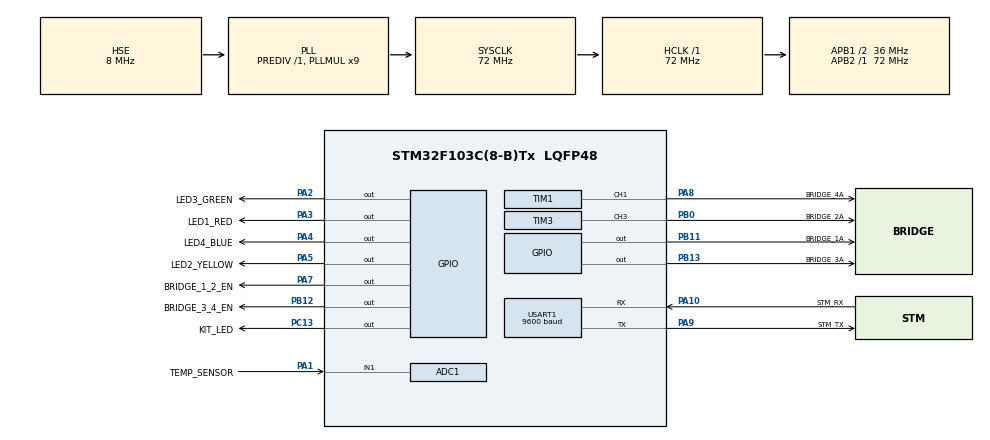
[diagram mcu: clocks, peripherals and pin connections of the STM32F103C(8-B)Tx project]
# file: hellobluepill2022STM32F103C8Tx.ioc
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ADC1.Channel-0\#ChannelRegularConversion=ADC_CHANNEL_1
ADC1.NbrOfConversionFlag=1
ADC1.Rank-0\#ChannelRegularConversion=1
ADC1.SamplingTime-0\#ChannelRegularConversion=ADC_SAMPLETIME_1CYCLE_5
ADC1.master=1
Dma.Request0=USART1_RX
Dma.Request1=USART1_TX
Dma.USART1_RX.0.Direction=DMA_PERIPH_TO_MEMORY
Dma.USART1_RX.0.Instance=DMA1_Channel5
Dma.USART1_RX.0.MemDataAlignment=DMA_MDATAALIGN_BYTE
Dma.USART1_RX.0.MemInc=DMA_MINC_ENABLE
Dma.USART1_RX.0.Mode=DMA_NORMAL
Dma.USART1_RX.0.PeriphDataAlignment=DMA_PDATAALIGN_BYTE
Dma.USART1_RX.0.PeriphInc=DMA_PINC_DISABLE
Dma.USART1_RX.0.Priority=DMA_PRIORITY_LOW
Dma.USART1_TX.1.Direction=DMA_MEMORY_TO_PERIPH
Dma.USART1_TX.1.Instance=DMA1_Channel4
Dma.USART1_TX.1.MemDataAlignment=DMA_MDATAALIGN_BYTE
Dma.USART1_TX.1.MemInc=DMA_MINC_ENABLE
Dma.USART1_TX.1.Mode=DMA_NORMAL
Dma.USART1_TX.1.PeriphDataAlignment=DMA_PDATAALIGN_BYTE
Dma.USART1_TX.1.PeriphInc=DMA_PINC_DISABLE
Dma.USART1_TX.1.Priority=DMA_PRIORITY_LOW
FREERTOS.BinarySemaphores01=ATCommandSemaphore,Static,ATCommandSemaphoreControlBlock;ATResponseSemaphore,Static,ATResponseSemaphoreControlBlock;UARTTXSemaphore,Static,UARTTXSemaphoreControlBlock;RadioStateSemaphore,Static,RadioStateSemaphoreControlBlock;LoRaTXSemaphore,Static,LoRaTXSemaphoreControlBlock
FREERTOS.Events01=ModemStatusFlags,Static,ModemStatusFlagsControlBlock
FREERTOS.Queues01=uartQueue,4,void*,0,Static,uartQueueBuffer,uartQueueControlBlock;ATQueue,4,void*,0,Static,ATQueueBuffer,ATQueueControlBlock;ModemSendQueue,4,void*,0,Static,ModemSendQueueBuffer,ModemSendQueueControlBlock;TemperatureQueue,8,uint32_t,0,Static,TemperatureQueueBuffer,TemperatureQueueControlBlock
FREERTOS.Tasks01=defaultTask,24,128,StartDefaultTask,Default,NULL,Dynamic,NULL,NULL;ATParsingTask,39,256,ATParsingTaskCode,As external,NULL,Static,ATParsingTaskBuffer,ATParsingTaskControlBlock;ATHandlingTask,38,256,ATHandlingTaskCode,As external,NULL,Static,ATHandlingTaskBuffer,ATHandlingTaskControlBlock;UARTProcTask,47,256,UARTProcTaskCode,As external,NULL,Static,UARTProcTaskBuffer,UARTProcTaskControlBlock;ModemMngrTask,31,256,ModemManagerTaskCode,As external,NULL,Static,ModemMngrTaskBuffer,ModemMngrTaskControlBlock;AppSendTask,15,256,AppSendTaskCode,As external,NULL,Static,SendTemperatureBuffer,SendTemperatureControlBlock;ReadFromADCTask,15,128,ReadFromADCTaskCode,As external,NULL,Static,ReadFromADCTaskBuffer,ReadFromADCTaskControlBlock
FREERTOS.Timers01=PeriodicSendTimer,PeriodicSendTimerCallback,osTimerPeriodic,As external,NULL,Static,PeriodicSendTimerControlBlock;ModemLedTimer,ModemLedCallback,osTimerPeriodic,As external,NULL,Static,ModemLedTimerControlBlock;DutyCycleTimer,DutyCycleTimerCallback,osTimerOnce,As external,NULL,Static,DutyCycleTimerControlBlock
FREERTOS.configTOTAL_HEAP_SIZE=2048
FREERTOS.configUSE_TICKLESS_IDLE=1
Mcu.Family=STM32F1
Mcu.Name=STM32F103C(8-B)Tx
Mcu.Package=LQFP48
NVIC.DMA1_Channel4_IRQn=true\:5\:0\:false\:false\:true\:true\:false\:true\:true
NVIC.DMA1_Channel5_IRQn=true\:5\:0\:false\:false\:true\:true\:false\:true\:true
NVIC.PriorityGroup=NVIC_PRIORITYGROUP_4
NVIC.TIM1_TRG_COM_IRQn=true\:5\:0\:false\:false\:true\:true\:true\:true\:true
NVIC.TIM4_IRQn=true\:15\:0\:false\:false\:true\:false\:false\:true\:true
NVIC.TimeBase=TIM4_IRQn
NVIC.TimeBaseIP=TIM4
NVIC.USART1_IRQn=true\:5\:0\:false\:false\:true\:true\:true\:true\:true
PA1.GPIO_Label=TEMP_SENSOR
PA1.Signal=ADCx_IN1
PA10.GPIO_Label=STM_RX
PA10.Mode=Asynchronous
PA10.Signal=USART1_RX
PA13.Mode=Serial_Wire
PA13.Signal=SYS_JTMS-SWDIO
PA14.Mode=Serial_Wire
PA14.Signal=SYS_JTCK-SWCLK
PA2.GPIO_Label=LED3_GREEN
PA2.Signal=GPIO_Output
PA3.GPIO_Label=LED1_RED
PA3.Signal=GPIO_Output
PA4.GPIO_Label=LED4_BLUE
PA4.Signal=GPIO_Output
PA5.GPIO_Label=LED2_YELLOW
PA5.Signal=GPIO_Output
PA7.GPIO_Label=BRIDGE_1_2_EN
PA7.PinState=GPIO_PIN_SET
PA7.Signal=GPIO_Output
PA8.GPIO_Label=BRIDGE_4A
PA8.Signal=S_TIM1_CH1
PA9.GPIO_Label=STM_TX
PA9.Mode=Asynchronous
PA9.Signal=USART1_TX
PB0.GPIO_Label=BRIDGE_2A
PB0.Signal=S_TIM3_CH3
PB11.GPIO_Label=BRIDGE_1A
PB11.PinState=GPIO_PIN_RESET
PB11.Signal=GPIO_Output
PB12.GPIO_Label=BRIDGE_3_4_EN
PB12.PinState=GPIO_PIN_SET
PB12.Signal=GPIO_Output
PB13.GPIO_Label=BRIDGE_3A
PB13.Signal=GPIO_Output
PC13-TAMPER-RTC.GPIO_Label=KIT_LED
PC13-TAMPER-RTC.Signal=GPIO_Output
PC14-OSC32_IN.Mode=LSE-External-Oscillator
PC14-OSC32_IN.Signal=RCC_OSC32_IN
PC15-OSC32_OUT.Mode=LSE-External-Oscillator
PC15-OSC32_OUT.Signal=RCC_OSC32_OUT
PD0-OSC_IN.Mode=HSE-External-Oscillator
PD0-OSC_IN.Signal=RCC_OSC_IN
PD1-OSC_OUT.Mode=HSE-External-Oscillator
PD1-OSC_OUT.Signal=RCC_OSC_OUT
ProjectManager.HeapSize=0x200
ProjectManager.StackSize=0x400
ProjectManager.TargetToolchain=Makefile
RCC.ADCPresc=RCC_ADCPCLK2_DIV6
RCC.AHBFreq_Value=72000000
RCC.APB1CLKDivider=RCC_HCLK_DIV2
RCC.APB1Freq_Value=36000000
RCC.APB1TimFreq_Value=72000000
RCC.APB2Freq_Value=72000000
RCC.APB2TimFreq_Value=72000000
RCC.HCLKFreq_Value=72000000
RCC.PLLMUL=RCC_PLL_MUL9
RCC.PLLSourceVirtual=RCC_PLLSOURCE_HSE
RCC.SYSCLKFreq_VALUE=72000000
RCC.SYSCLKSource=RCC_SYSCLKSOURCE_PLLCLK
RCC.USBFreq_Value=48000000
RCC.USBPrescaler=RCC_USBCLKSOURCE_PLL_DIV1_5
SH.ADCx_IN1.0=ADC1_IN1,IN1
SH.S_TIM1_CH1.0=TIM1_CH1,Output Compare1 CH1
SH.S_TIM3_CH3.0=TIM3_CH3,PWM Generation3 CH3
TIM1.Channel-Output\ Compare1\ CH1=TIM_CHANNEL_1
TIM1.OC1Preload=ENABLE
TIM1.OCMode_1=TIM_OCMODE_TOGGLE
TIM1.Period=7200-1
TIM1.Pulse-Output\ Compare1\ CH1=7200-1
TIM3.Channel-PWM\ Generation3\ CH3=TIM_CHANNEL_3
TIM3.Period=7200-1
TIM3.Prescaler=0
TIM3.Pulse-PWM\ Generation3\ CH3=7200-1
USART1.BaudRate=9600
USART1.VirtualMode=VM_ASYNC
VP_FREERTOS_VS_CMSIS_V2.Mode=CMSIS_V2
VP_SYS_VS_tim4.Mode=TIM4
VP_TIM1_VS_ClockSourceINT.Mode=Internal
VP_TIM3_VS_ClockSourceINT.Mode=Internal
board=custom

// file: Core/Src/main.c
/* USER CODE BEGIN Header */
/**
  ******************************************************************************
  * @file           : main.c
  * @brief          : Main program body
  ******************************************************************************
  * @attention
  *
  * Copyright (c) 2022 STMicroelectronics.
  * All rights reserved.
  *
  * This software is licensed under terms that can be found in the LICENSE file
  * in the root directory of this software component.
  * If no LICENSE file comes with this software, it is provided AS-IS.
  *
  ******************************************************************************
  */
/* USER CODE END Header */
#include "main.h"
#include "cmsis_os.h"

typedef StaticTask_t osStaticThreadDef_t;
typedef StaticQueue_t osStaticMessageQDef_t;
typedef StaticTimer_t osStaticTimerDef_t;
typedef StaticSemaphore_t osStaticSemaphoreDef_t;
typedef StaticEventGroup_t osStaticEventGroupDef_t;

ADC_HandleTypeDef hadc1;

TIM_HandleTypeDef htim1;
TIM_HandleTypeDef htim3;

UART_HandleTypeDef huart1;
DMA_HandleTypeDef hdma_usart1_rx;
DMA_HandleTypeDef hdma_usart1_tx;

/* Definitions for defaultTask */
osThreadId_t defaultTaskHandle;
const osThreadAttr_t defaultTask_attributes = {
  .name = "defaultTask",
  .stack_size = 128 * 4,
  .priority = (osPriority_t) osPriorityNormal,
};
/* Definitions for ATParsingTask */
osThreadId_t ATParsingTaskHandle;
uint32_t ATParsingTaskBuffer[ 256 ];
osStaticThreadDef_t ATParsingTaskControlBlock;
const osThreadAttr_t ATParsingTask_attributes = {
  .name = "ATParsingTask",
  .cb_mem = &ATParsingTaskControlBlock,
  .cb_size = sizeof(ATParsingTaskControlBlock),
  .stack_mem = &ATParsingTaskBuffer[0],
  .stack_size = sizeof(ATParsingTaskBuffer),
  .priority = (osPriority_t) osPriorityAboveNormal7,
};
/* Definitions for ATHandlingTask */
osThreadId_t ATHandlingTaskHandle;
uint32_t ATHandlingTaskBuffer[ 256 ];
osStaticThreadDef_t ATHandlingTaskControlBlock;
const osThreadAttr_t ATHandlingTask_attributes = {
  .name = "ATHandlingTask",
  .cb_mem = &ATHandlingTaskControlBlock,
  .cb_size = sizeof(ATHandlingTaskControlBlock),
  .stack_mem = &ATHandlingTaskBuffer[0],
  .stack_size = sizeof(ATHandlingTaskBuffer),
  .priority = (osPriority_t) osPriorityAboveNormal6,
};
/* Definitions for UARTProcTask */
osThreadId_t UARTProcTaskHandle;
uint32_t UARTProcTaskBuffer[ 256 ];
osStaticThreadDef_t UARTProcTaskControlBlock;
const osThreadAttr_t UARTProcTask_attributes = {
  .name = "UARTProcTask",
  .cb_mem = &UARTProcTaskControlBlock,
  .cb_size = sizeof(UARTProcTaskControlBlock),
  .stack_mem = &UARTProcTaskBuffer[0],
  .stack_size = sizeof(UARTProcTaskBuffer),
  .priority = (osPriority_t) osPriorityHigh7,
};
/* Definitions for ModemMngrTask */
osThreadId_t ModemMngrTaskHandle;
uint32_t ModemMngrTaskBuffer[ 256 ];
osStaticThreadDef_t ModemMngrTaskControlBlock;
const osThreadAttr_t ModemMngrTask_attributes = {
  .name = "ModemMngrTask",
  .cb_mem = &ModemMngrTaskControlBlock,
  .cb_size = sizeof(ModemMngrTaskControlBlock),
  .stack_mem = &ModemMngrTaskBuffer[0],
  .stack_size = sizeof(ModemMngrTaskBuffer),
  .priority = (osPriority_t) osPriorityNormal7,
};
/* Definitions for AppSendTask */
osThreadId_t AppSendTaskHandle;
uint32_t SendTemperatureBuffer[ 256 ];
osStaticThreadDef_t SendTemperatureControlBlock;
const osThreadAttr_t AppSendTask_attributes = {
  .name = "AppSendTask",
  .cb_mem = &SendTemperatureControlBlock,
  .cb_size = sizeof(SendTemperatureControlBlock),
  .stack_mem = &SendTemperatureBuffer[0],
  .stack_size = sizeof(SendTemperatureBuffer),
  .priority = (osPriority_t) osPriorityLow7,
};
/* Definitions for ReadFromADCTask */
osThreadId_t ReadFromADCTaskHandle;
uint32_t ReadFromADCTaskBuffer[ 128 ];
osStaticThreadDef_t ReadFromADCTaskControlBlock;
const osThreadAttr_t ReadFromADCTask_attributes = {
  .name = "ReadFromADCTask",
  .cb_mem = &ReadFromADCTaskControlBlock,
  .cb_size = sizeof(ReadFromADCTaskControlBlock),
  .stack_mem = &ReadFromADCTaskBuffer[0],
  .stack_size = sizeof(ReadFromADCTaskBuffer),
  .priority = (osPriority_t) osPriorityLow7,
};
/* Definitions for uartQueue */
osMessageQueueId_t uartQueueHandle;
uint8_t uartQueueBuffer[ 4 * sizeof( void* ) ];
osStaticMessageQDef_t uartQueueControlBlock;
const osMessageQueueAttr_t uartQueue_attributes = {
  .name = "uartQueue",
  .cb_mem = &uartQueueControlBlock,
  .cb_size = sizeof(uartQueueControlBlock),
  .mq_mem = &uartQueueBuffer,
  .mq_size = sizeof(uartQueueBuffer)
};
/* Definitions for ATQueue */
osMessageQueueId_t ATQueueHandle;
uint8_t ATQueueBuffer[ 4 * sizeof( void* ) ];
osStaticMessageQDef_t ATQueueControlBlock;
const osMessageQueueAttr_t ATQueue_attributes = {
  .name = "ATQueue",
  .cb_mem = &ATQueueControlBlock,
  .cb_size = sizeof(ATQueueControlBlock),
  .mq_mem = &ATQueueBuffer,
  .mq_size = sizeof(ATQueueBuffer)
};
/* Definitions for ModemSendQueue */
osMessageQueueId_t ModemSendQueueHandle;
uint8_t ModemSendQueueBuffer[ 4 * sizeof( void* ) ];
osStaticMessageQDef_t ModemSendQueueControlBlock;
const osMessageQueueAttr_t ModemSendQueue_attributes = {
  .name = "ModemSendQueue",
  .cb_mem = &ModemSendQueueControlBlock,
  .cb_size = sizeof(ModemSendQueueControlBlock),
  .mq_mem = &ModemSendQueueBuffer,
  .mq_size = sizeof(ModemSendQueueBuffer)
};
/* Definitions for PeriodicSendTimer */
osTimerId_t PeriodicSendTimerHandle;
osStaticTimerDef_t PeriodicSendTimerControlBlock;
const osTimerAttr_t PeriodicSendTimer_attributes = {
  .name = "PeriodicSendTimer",
  .cb_mem = &PeriodicSendTimerControlBlock,
  .cb_size = sizeof(PeriodicSendTimerControlBlock),
};
/* Definitions for TemperatureQueue */
osMessageQueueId_t TemperatureQueueHandle;
uint8_t TemperatureQueueBuffer[ 8 * sizeof( uint32_t ) ];
osStaticMessageQDef_t TemperatureQueueControlBlock;
const osMessageQueueAttr_t TemperatureQueue_attributes = {
  .name = "TemperatureQueue",
  .cb_mem = &TemperatureQueueControlBlock,
  .cb_size = sizeof(TemperatureQueueControlBlock),
  .mq_mem = &TemperatureQueueBuffer,
  .mq_size = sizeof(TemperatureQueueBuffer)
};
/* Definitions for ModemLedTimer */
osTimerId_t ModemLedTimerHandle;
osStaticTimerDef_t ModemLedTimerControlBlock;
const osTimerAttr_t ModemLedTimer_attributes = {
  .name = "ModemLedTimer",
  .cb_mem = &ModemLedTimerControlBlock,
  .cb_size = sizeof(ModemLedTimerControlBlock),
};
/* Definitions for DutyCycleTimer */
osTimerId_t DutyCycleTimerHandle;
osStaticTimerDef_t DutyCycleTimerControlBlock;
const osTimerAttr_t DutyCycleTimer_attributes = {
  .name = "DutyCycleTimer",
  .cb_mem = &DutyCycleTimerControlBlock,
  .cb_size = sizeof(DutyCycleTimerControlBlock),
};
/* Definitions for ATCommandSemaphore */
osSemaphoreId_t ATCommandSemaphoreHandle;
osStaticSemaphoreDef_t ATCommandSemaphoreControlBlock;
const osSemaphoreAttr_t ATCommandSemaphore_attributes = {
  .name = "ATCommandSemaphore",
  .cb_mem = &ATCommandSemaphoreControlBlock,
  .cb_size = sizeof(ATCommandSemaphoreControlBlock),
};
/* Definitions for ATResponseSemaphore */
osSemaphoreId_t ATResponseSemaphoreHandle;
osStaticSemaphoreDef_t ATResponseSemaphoreControlBlock;
const osSemaphoreAttr_t ATResponseSemaphore_attributes = {
  .name = "ATResponseSemaphore",
  .cb_mem = &ATResponseSemaphoreControlBlock,
  .cb_size = sizeof(ATResponseSemaphoreControlBlock),
};
/* Definitions for UARTTXSemaphore */
osSemaphoreId_t UARTTXSemaphoreHandle;
osStaticSemaphoreDef_t UARTTXSemaphoreControlBlock;
const osSemaphoreAttr_t UARTTXSemaphore_attributes = {
  .name = "UARTTXSemaphore",
  .cb_mem = &UARTTXSemaphoreControlBlock,
  .cb_size = sizeof(UARTTXSemaphoreControlBlock),
};
/* Definitions for RadioStateSemaphore */
osSemaphoreId_t RadioStateSemaphoreHandle;
osStaticSemaphoreDef_t RadioStateSemaphoreControlBlock;
const osSemaphoreAttr_t RadioStateSemaphore_attributes = {
  .name = "RadioStateSemaphore",
  .cb_mem = &RadioStateSemaphoreControlBlock,
  .cb_size = sizeof(RadioStateSemaphoreControlBlock),
};
/* Definitions for LoRaTXSemaphore */
osSemaphoreId_t LoRaTXSemaphoreHandle;
osStaticSemaphoreDef_t LoRaTXSemaphoreControlBlock;
const osSemaphoreAttr_t LoRaTXSemaphore_attributes = {
  .name = "LoRaTXSemaphore",
  .cb_mem = &LoRaTXSemaphoreControlBlock,
  .cb_size = sizeof(LoRaTXSemaphoreControlBlock),
};
/* Definitions for ModemStatusFlags */
osEventFlagsId_t ModemStatusFlagsHandle;
osStaticEventGroupDef_t ModemStatusFlagsControlBlock;
const osEventFlagsAttr_t ModemStatusFlags_attributes = {
  .name = "ModemStatusFlags",
  .cb_mem = &ModemStatusFlagsControlBlock,
  .cb_size = sizeof(ModemStatusFlagsControlBlock),
};

void SystemClock_Config(void);
static void MX_GPIO_Init(void);
static void MX_DMA_Init(void);
static void MX_USART1_UART_Init(void);
static void MX_ADC1_Init(void);
static void MX_TIM3_Init(void);
static void MX_TIM1_Init(void);
void StartDefaultTask(void *argument);
extern void ATParsingTaskCode(void *argument);
extern void ATHandlingTaskCode(void *argument);
extern void UARTProcTaskCode(void *argument);
extern void ModemManagerTaskCode(void *argument);
extern void AppSendTaskCode(void *argument);
extern void PeriodicSendTimerCallback(void *argument);
extern void ReadFromADCTaskCode(void *argument);
extern void ModemLedCallback(void *argument);
extern void DutyCycleTimerCallback(void *argument);

/* USER CODE BEGIN PFP */
void CONFIGURE_TIMER_FOR_RUN_TIME_STATS()
{
  HAL_TIM_Base_Start(&htim3); /* Define this to initialize your timer/counter */
}

uint32_t GET_RUN_TIME_COUNTER_VALUE()
{
  return __HAL_TIM_GET_COUNTER(&htim3); /* Define this to sample the timer/counter */
}

/* USER CODE END PFP */

/* USER CODE BEGIN 0 */
const volatile int uxTopUsedPriority = configMAX_PRIORITIES - 1; //this declaration enables thread awareness for FreeRTOS using OpenOCD

// Paste this code to Core/Inc/FreeRTOSConfig.h to enable kernel statistics (will be overwritten by STMCubeMX everytime code is generated)
// #define portCONFIGURE_TIMER_FOR_RUN_TIME_STATS() CONFIGURE_TIMER_FOR_RUN_TIME_STATS()/* Define this to initialize your timer/counter */
// #define portGET_RUN_TIME_COUNTER_VALUE() GET_RUN_TIME_COUNTER_VALUE()        /* Define this to sample the timer/counter */
// #define configGENERATE_RUN_TIME_STATS (1)
// #define configRECORD_STACK_HIGH_ADDRESS (1)
/* USER CODE END 0 */

int main(void)
{
  /* USER CODE BEGIN 1 */
  uint32_t i;
  (void)uxTopUsedPriority; //this declaration enables thread awareness for FreeRTOS using OpenOCD
  /* USER CODE END 1 */

  /* MCU Configuration--------------------------------------------------------*/

  /* Reset of all peripherals, Initializes the Flash interface and the Systick. */
  HAL_Init();

  /* Configure the system clock */
  SystemClock_Config();

  /* Initialize all configured peripherals */
  MX_GPIO_Init();
  MX_DMA_Init();
  MX_USART1_UART_Init();
  MX_ADC1_Init();
  MX_TIM3_Init();
  MX_TIM1_Init();

  /* Init scheduler */
  osKernelInitialize();

  /* Create the semaphores(s) */
  /* creation of ATCommandSemaphore */
  ATCommandSemaphoreHandle = osSemaphoreNew(1, 1, &ATCommandSemaphore_attributes);

  /* creation of ATResponseSemaphore */
  ATResponseSemaphoreHandle = osSemaphoreNew(1, 1, &ATResponseSemaphore_attributes);

  /* creation of UARTTXSemaphore */
  UARTTXSemaphoreHandle = osSemaphoreNew(1, 1, &UARTTXSemaphore_attributes);

  /* creation of RadioStateSemaphore */
  RadioStateSemaphoreHandle = osSemaphoreNew(1, 1, &RadioStateSemaphore_attributes);

  /* creation of LoRaTXSemaphore */
  LoRaTXSemaphoreHandle = osSemaphoreNew(1, 1, &LoRaTXSemaphore_attributes);

  /* Create the timer(s) */
  /* creation of PeriodicSendTimer */
  PeriodicSendTimerHandle = osTimerNew(PeriodicSendTimerCallback, osTimerPeriodic, NULL, &PeriodicSendTimer_attributes);

  /* creation of ModemLedTimer */
  ModemLedTimerHandle = osTimerNew(ModemLedCallback, osTimerPeriodic, NULL, &ModemLedTimer_attributes);

  /* creation of DutyCycleTimer */
  DutyCycleTimerHandle = osTimerNew(DutyCycleTimerCallback, osTimerOnce, NULL, &DutyCycleTimer_attributes);

  /* Create the queue(s) */
  /* creation of uartQueue */
  uartQueueHandle = osMessageQueueNew (4, sizeof(void*), &uartQueue_attributes);

  /* creation of ATQueue */
  ATQueueHandle = osMessageQueueNew (4, sizeof(void*), &ATQueue_attributes);

  /* creation of ModemSendQueue */
  ModemSendQueueHandle = osMessageQueueNew (4, sizeof(void*), &ModemSendQueue_attributes);

  /* creation of TemperatureQueue */
  TemperatureQueueHandle = osMessageQueueNew (8, sizeof(uint32_t), &TemperatureQueue_attributes);

  /* Create the thread(s) */
  /* creation of defaultTask */
  defaultTaskHandle = osThreadNew(StartDefaultTask, NULL, &defaultTask_attributes);

  /* creation of ATParsingTask */
  ATParsingTaskHandle = osThreadNew(ATParsingTaskCode, NULL, &ATParsingTask_attributes);

  /* creation of ATHandlingTask */
  ATHandlingTaskHandle = osThreadNew(ATHandlingTaskCode, NULL, &ATHandlingTask_attributes);

  /* creation of UARTProcTask */
  UARTProcTaskHandle = osThreadNew(UARTProcTaskCode, NULL, &UARTProcTask_attributes);

  /* creation of ModemMngrTask */
  ModemMngrTaskHandle = osThreadNew(ModemManagerTaskCode, NULL, &ModemMngrTask_attributes);

  /* creation of AppSendTask */
  AppSendTaskHandle = osThreadNew(AppSendTaskCode, NULL, &AppSendTask_attributes);

  /* creation of ReadFromADCTask */
  ReadFromADCTaskHandle = osThreadNew(ReadFromADCTaskCode, NULL, &ReadFromADCTask_attributes);

  /* Create the event(s) */
  /* creation of ModemStatusFlags */
  ModemStatusFlagsHandle = osEventFlagsNew(&ModemStatusFlags_attributes);

  /* Start scheduler */
  osKernelStart();
  /* We should never get here as control is now taken by the scheduler */
  /* Infinite loop */
  /* USER CODE BEGIN WHILE */
  while (1)
  {
    for (i = 0; i < 13; i++)
    {
      HAL_GPIO_WritePin(KIT_LED_GPIO_Port, KIT_LED_Pin, 0);
      HAL_Delay(25);
      HAL_GPIO_WritePin(KIT_LED_GPIO_Port, KIT_LED_Pin, 1);
      HAL_Delay(50);
    }
    HAL_Delay(800);

    /* USER CODE END WHILE */

  }
}

void SystemClock_Config(void)
{
  RCC_OscInitTypeDef RCC_OscInitStruct = {0};
  RCC_ClkInitTypeDef RCC_ClkInitStruct = {0};
  RCC_PeriphCLKInitTypeDef PeriphClkInit = {0};

  /** Initializes the RCC Oscillators according to the specified parameters
  * in the RCC_OscInitTypeDef structure.
  */
  RCC_OscInitStruct.OscillatorType = RCC_OSCILLATORTYPE_HSE;
  RCC_OscInitStruct.HSEState = RCC_HSE_ON;
  RCC_OscInitStruct.HSEPredivValue = RCC_HSE_PREDIV_DIV1;
  RCC_OscInitStruct.HSIState = RCC_HSI_ON;
  RCC_OscInitStruct.PLL.PLLState = RCC_PLL_ON;
  RCC_OscInitStruct.PLL.PLLSource = RCC_PLLSOURCE_HSE;
  RCC_OscInitStruct.PLL.PLLMUL = RCC_PLL_MUL9;
  if (HAL_RCC_OscConfig(&RCC_OscInitStruct) != HAL_OK)
  {
    Error_Handler();
  }

  /** Initializes the CPU, AHB and APB buses clocks
  */
  RCC_ClkInitStruct.ClockType = RCC_CLOCKTYPE_HCLK|RCC_CLOCKTYPE_SYSCLK
                              |RCC_CLOCKTYPE_PCLK1|RCC_CLOCKTYPE_PCLK2;
  RCC_ClkInitStruct.SYSCLKSource = RCC_SYSCLKSOURCE_PLLCLK;
  RCC_ClkInitStruct.AHBCLKDivider = RCC_SYSCLK_DIV1;
  RCC_ClkInitStruct.APB1CLKDivider = RCC_HCLK_DIV2;
  RCC_ClkInitStruct.APB2CLKDivider = RCC_HCLK_DIV1;

  if (HAL_RCC_ClockConfig(&RCC_ClkInitStruct, FLASH_LATENCY_2) != HAL_OK)
  {
    Error_Handler();
  }
  PeriphClkInit.PeriphClockSelection = RCC_PERIPHCLK_ADC;
  PeriphClkInit.AdcClockSelection = RCC_ADCPCLK2_DIV6;
  if (HAL_RCCEx_PeriphCLKConfig(&PeriphClkInit) != HAL_OK)
  {
    Error_Handler();
  }
}

static void MX_ADC1_Init(void)
{

  ADC_ChannelConfTypeDef sConfig = {0};

  /** Common config
  */
  hadc1.Instance = ADC1;
  hadc1.Init.ScanConvMode = ADC_SCAN_DISABLE;
  hadc1.Init.ContinuousConvMode = DISABLE;
  hadc1.Init.DiscontinuousConvMode = DISABLE;
  hadc1.Init.ExternalTrigConv = ADC_SOFTWARE_START;
  hadc1.Init.DataAlign = ADC_DATAALIGN_RIGHT;
  hadc1.Init.NbrOfConversion = 1;
  if (HAL_ADC_Init(&hadc1) != HAL_OK)
  {
    Error_Handler();
  }

  /** Configure Regular Channel
  */
  sConfig.Channel = ADC_CHANNEL_1;
  sConfig.Rank = ADC_REGULAR_RANK_1;
  sConfig.SamplingTime = ADC_SAMPLETIME_1CYCLE_5;
  if (HAL_ADC_ConfigChannel(&hadc1, &sConfig) != HAL_OK)
  {
    Error_Handler();
  }

}

static void MX_TIM1_Init(void)
{

  TIM_ClockConfigTypeDef sClockSourceConfig = {0};
  TIM_MasterConfigTypeDef sMasterConfig = {0};
  TIM_OC_InitTypeDef sConfigOC = {0};
  TIM_BreakDeadTimeConfigTypeDef sBreakDeadTimeConfig = {0};

  htim1.Instance = TIM1;
  htim1.Init.Prescaler = 0;
  htim1.Init.CounterMode = TIM_COUNTERMODE_UP;
  htim1.Init.Period = 7200-1;
  htim1.Init.ClockDivision = TIM_CLOCKDIVISION_DIV1;
  htim1.Init.RepetitionCounter = 0;
  htim1.Init.AutoReloadPreload = TIM_AUTORELOAD_PRELOAD_DISABLE;
  if (HAL_TIM_Base_Init(&htim1) != HAL_OK)
  {
    Error_Handler();
  }
  sClockSourceConfig.ClockSource = TIM_CLOCKSOURCE_INTERNAL;
  if (HAL_TIM_ConfigClockSource(&htim1, &sClockSourceConfig) != HAL_OK)
  {
    Error_Handler();
  }
  if (HAL_TIM_OC_Init(&htim1) != HAL_OK)
  {
    Error_Handler();
  }
  sMasterConfig.MasterOutputTrigger = TIM_TRGO_RESET;
  sMasterConfig.MasterSlaveMode = TIM_MASTERSLAVEMODE_DISABLE;
  if (HAL_TIMEx_MasterConfigSynchronization(&htim1, &sMasterConfig) != HAL_OK)
  {
    Error_Handler();
  }
  sConfigOC.OCMode = TIM_OCMODE_TOGGLE;
  sConfigOC.Pulse = 7200-1;
  sConfigOC.OCPolarity = TIM_OCPOLARITY_HIGH;
  sConfigOC.OCNPolarity = TIM_OCNPOLARITY_HIGH;
  sConfigOC.OCFastMode = TIM_OCFAST_DISABLE;
  sConfigOC.OCIdleState = TIM_OCIDLESTATE_RESET;
  sConfigOC.OCNIdleState = TIM_OCNIDLESTATE_RESET;
  if (HAL_TIM_OC_ConfigChannel(&htim1, &sConfigOC, TIM_CHANNEL_1) != HAL_OK)
  {
    Error_Handler();
  }
  __HAL_TIM_ENABLE_OCxPRELOAD(&htim1, TIM_CHANNEL_1);
  sBreakDeadTimeConfig.OffStateRunMode = TIM_OSSR_DISABLE;
  sBreakDeadTimeConfig.OffStateIDLEMode = TIM_OSSI_DISABLE;
  sBreakDeadTimeConfig.LockLevel = TIM_LOCKLEVEL_OFF;
  sBreakDeadTimeConfig.DeadTime = 0;
  sBreakDeadTimeConfig.BreakState = TIM_BREAK_DISABLE;
  sBreakDeadTimeConfig.BreakPolarity = TIM_BREAKPOLARITY_HIGH;
  sBreakDeadTimeConfig.AutomaticOutput = TIM_AUTOMATICOUTPUT_DISABLE;
  if (HAL_TIMEx_ConfigBreakDeadTime(&htim1, &sBreakDeadTimeConfig) != HAL_OK)
  {
    Error_Handler();
  }
  HAL_TIM_MspPostInit(&htim1);

}

static void MX_TIM3_Init(void)
{

  TIM_ClockConfigTypeDef sClockSourceConfig = {0};
  TIM_MasterConfigTypeDef sMasterConfig = {0};
  TIM_OC_InitTypeDef sConfigOC = {0};

  htim3.Instance = TIM3;
  htim3.Init.Prescaler = 0;
  htim3.Init.CounterMode = TIM_COUNTERMODE_UP;
  htim3.Init.Period = 7200-1;
  htim3.Init.ClockDivision = TIM_CLOCKDIVISION_DIV1;
  htim3.Init.AutoReloadPreload = TIM_AUTORELOAD_PRELOAD_DISABLE;
  if (HAL_TIM_Base_Init(&htim3) != HAL_OK)
  {
    Error_Handler();
  }
  sClockSourceConfig.ClockSource = TIM_CLOCKSOURCE_INTERNAL;
  if (HAL_TIM_ConfigClockSource(&htim3, &sClockSourceConfig) != HAL_OK)
  {
    Error_Handler();
  }
  if (HAL_TIM_PWM_Init(&htim3) != HAL_OK)
  {
    Error_Handler();
  }
  sMasterConfig.MasterOutputTrigger = TIM_TRGO_RESET;
  sMasterConfig.MasterSlaveMode = TIM_MASTERSLAVEMODE_DISABLE;
  if (HAL_TIMEx_MasterConfigSynchronization(&htim3, &sMasterConfig) != HAL_OK)
  {
    Error_Handler();
  }
  sConfigOC.OCMode = TIM_OCMODE_PWM1;
  sConfigOC.Pulse = 7200-1;
  sConfigOC.OCPolarity = TIM_OCPOLARITY_HIGH;
  sConfigOC.OCFastMode = TIM_OCFAST_DISABLE;
  if (HAL_TIM_PWM_ConfigChannel(&htim3, &sConfigOC, TIM_CHANNEL_3) != HAL_OK)
  {
    Error_Handler();
  }
  HAL_TIM_MspPostInit(&htim3);

}

static void MX_USART1_UART_Init(void)
{

  huart1.Instance = USART1;
  huart1.Init.BaudRate = 9600;
  huart1.Init.WordLength = UART_WORDLENGTH_8B;
  huart1.Init.StopBits = UART_STOPBITS_1;
  huart1.Init.Parity = UART_PARITY_NONE;
  huart1.Init.Mode = UART_MODE_TX_RX;
  huart1.Init.HwFlowCtl = UART_HWCONTROL_NONE;
  huart1.Init.OverSampling = UART_OVERSAMPLING_16;
  if (HAL_UART_Init(&huart1) != HAL_OK)
  {
    Error_Handler();
  }

}

static void MX_DMA_Init(void)
{

  /* DMA controller clock enable */
  __HAL_RCC_DMA1_CLK_ENABLE();

  /* DMA interrupt init */
  /* DMA1_Channel4_IRQn interrupt configuration */
  HAL_NVIC_SetPriority(DMA1_Channel4_IRQn, 5, 0);
  HAL_NVIC_EnableIRQ(DMA1_Channel4_IRQn);
  /* DMA1_Channel5_IRQn interrupt configuration */
  HAL_NVIC_SetPriority(DMA1_Channel5_IRQn, 5, 0);
  HAL_NVIC_EnableIRQ(DMA1_Channel5_IRQn);

}

static void MX_GPIO_Init(void)
{
  GPIO_InitTypeDef GPIO_InitStruct = {0};

  /* GPIO Ports Clock Enable */
  __HAL_RCC_GPIOC_CLK_ENABLE();
  __HAL_RCC_GPIOD_CLK_ENABLE();
  __HAL_RCC_GPIOA_CLK_ENABLE();
  __HAL_RCC_GPIOB_CLK_ENABLE();

  /*Configure GPIO pin Output Level */
  HAL_GPIO_WritePin(KIT_LED_GPIO_Port, KIT_LED_Pin, GPIO_PIN_RESET);

  /*Configure GPIO pin Output Level */
  HAL_GPIO_WritePin(GPIOA, LED3_GREEN_Pin|LED1_RED_Pin|LED4_BLUE_Pin|LED2_YELLOW_Pin, GPIO_PIN_RESET);

  /*Configure GPIO pin Output Level */
  HAL_GPIO_WritePin(BRIDGE_1_2_EN_GPIO_Port, BRIDGE_1_2_EN_Pin, GPIO_PIN_SET);

  /*Configure GPIO pin Output Level */
  HAL_GPIO_WritePin(GPIOB, BRIDGE_1A_Pin|BRIDGE_3A_Pin, GPIO_PIN_RESET);

  /*Configure GPIO pin Output Level */
  HAL_GPIO_WritePin(BRIDGE_3_4_EN_GPIO_Port, BRIDGE_3_4_EN_Pin, GPIO_PIN_SET);

  /*Configure GPIO pin : KIT_LED_Pin */
  GPIO_InitStruct.Pin = KIT_LED_Pin;
  GPIO_InitStruct.Mode = GPIO_MODE_OUTPUT_PP;
  GPIO_InitStruct.Pull = GPIO_NOPULL;
  GPIO_InitStruct.Speed = GPIO_SPEED_FREQ_LOW;
  HAL_GPIO_Init(KIT_LED_GPIO_Port, &GPIO_InitStruct);

  /*Configure GPIO pins : LED3_GREEN_Pin LED1_RED_Pin LED4_BLUE_Pin LED2_YELLOW_Pin
                           BRIDGE_1_2_EN_Pin */
  GPIO_InitStruct.Pin = LED3_GREEN_Pin|LED1_RED_Pin|LED4_BLUE_Pin|LED2_YELLOW_Pin
                          |BRIDGE_1_2_EN_Pin;
  GPIO_InitStruct.Mode = GPIO_MODE_OUTPUT_PP;
  GPIO_InitStruct.Pull = GPIO_NOPULL;
  GPIO_InitStruct.Speed = GPIO_SPEED_FREQ_LOW;
  HAL_GPIO_Init(GPIOA, &GPIO_InitStruct);

  /*Configure GPIO pins : BRIDGE_1A_Pin BRIDGE_3_4_EN_Pin BRIDGE_3A_Pin */
  GPIO_InitStruct.Pin = BRIDGE_1A_Pin|BRIDGE_3_4_EN_Pin|BRIDGE_3A_Pin;
  GPIO_InitStruct.Mode = GPIO_MODE_OUTPUT_PP;
  GPIO_InitStruct.Pull = GPIO_NOPULL;
  GPIO_InitStruct.Speed = GPIO_SPEED_FREQ_LOW;
  HAL_GPIO_Init(GPIOB, &GPIO_InitStruct);

}

void StartDefaultTask(void *argument)
{
  for(;;)
  {
    osDelay(1);
  }
}

void HAL_TIM_PeriodElapsedCallback(TIM_HandleTypeDef *htim)
{
  if (htim->Instance == TIM4) {
    HAL_IncTick();
  }
}

void Error_Handler(void)
{
  __disable_irq();
  while (1)
  {
  }
}

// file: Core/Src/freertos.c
/* USER CODE BEGIN Header */
/**
  ******************************************************************************
  * File Name          : freertos.c
  * Description        : Code for freertos applications
  ******************************************************************************
  * @attention
  *
  * Copyright (c) 2023 STMicroelectronics.
  * All rights reserved.
  *
  * This software is licensed under terms that can be found in the LICENSE file
  * in the root directory of this software component.
  * If no LICENSE file comes with this software, it is provided AS-IS.
  *
  ******************************************************************************
  */
/* USER CODE END Header */

#include "FreeRTOS.h"
#include "task.h"
#include "main.h"

/* USER CODE BEGIN PREPOSTSLEEP */
__weak void PreSleepProcessing(uint32_t *ulExpectedIdleTime)
{
/* place for user code */
}

__weak void PostSleepProcessing(uint32_t *ulExpectedIdleTime)
{
/* place for user code */
}
/* USER CODE END PREPOSTSLEEP */
